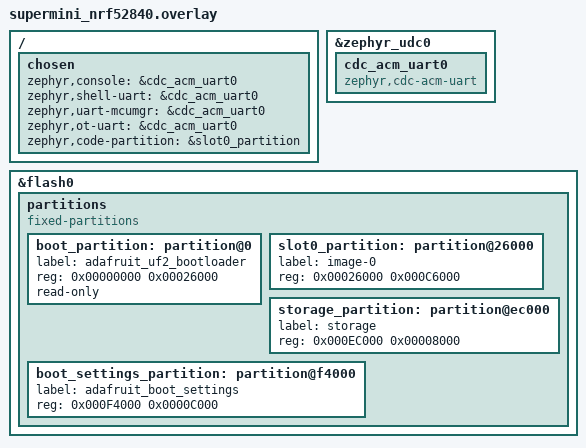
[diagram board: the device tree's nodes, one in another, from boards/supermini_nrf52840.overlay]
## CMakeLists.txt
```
#
# SuperMini nRF52840 Thread Network Health Checker
# Copyright (c) 2026 Antigravity
# SPDX-License-Identifier: Apache-2.0
#

cmake_minimum_required(VERSION 3.20.0)

find_package(Zephyr REQUIRED HINTS $ENV{ZEPHYR_BASE})
project(supermini_thread_health_checker)

target_sources(app PRIVATE
    src/main.cpp
    src/thread_health.cpp
)

target_include_directories(app PRIVATE src)
```

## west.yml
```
manifest:
  remotes:
    - name: zephyrproject-rtos
      url-base: https://github.com/zephyrproject-rtos

  defaults:
    remote: zephyrproject-rtos

  projects:
    - name: zephyr
      revision: v3.7.0
      import: true

  self:
    path: firmware
```

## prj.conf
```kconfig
#
# SuperMini nRF52840 Thread Network Health Checker - Zephyr & Matter Configuration
# Copyright (c) 2026 Antigravity
# SPDX-License-Identifier: Apache-2.0
#

# -----------------------------------------------------------------------------
# System & C++ Runtime
# -----------------------------------------------------------------------------
CONFIG_CPP=y
CONFIG_STD_CPP17=y
CONFIG_NEWLIB_LIBC=y
CONFIG_MAIN_STACK_SIZE=4096
CONFIG_SYSTEM_WORKQUEUE_STACK_SIZE=4096
CONFIG_HEAP_MEM_POOL_SIZE=16384
CONFIG_LOG=y
CONFIG_LOG_MODE_IMMEDIATE=y
CONFIG_PRINTK=y

# Flash Application Offset for Adafruit/nice!nano UF2 bootloader
CONFIG_FLASH_LOAD_OFFSET=0x26000
CONFIG_FLASH_LOAD_SIZE=0xc6000

# -----------------------------------------------------------------------------
# Clock Management (Crucial for SuperMini nRF52840 clones)
# Use internal 32.768 kHz RC oscillator to avoid hangs if external crystal is missing
# -----------------------------------------------------------------------------
CONFIG_CLOCK_CONTROL_NRF_K32SRC_RC=y
CONFIG_CLOCK_CONTROL_NRF_K32SRC_XTAL=n
CONFIG_CLOCK_CONTROL_NRF_K32SRC_500PPM=y

# -----------------------------------------------------------------------------
# USB CDC ACM Serial Console
# -----------------------------------------------------------------------------
CONFIG_USB_DEVICE_STACK=y
CONFIG_USB_DEVICE_PRODUCT="SuperMini Thread Health Checker"
CONFIG_USB_DEVICE_MANUFACTURER="Antigravity"
CONFIG_USB_DEVICE_VID=0x1915
CONFIG_USB_DEVICE_PID=0x520F
CONFIG_SERIAL=y
CONFIG_CONSOLE=y
CONFIG_UART_CONSOLE=y
CONFIG_UART_LINE_CTRL=y
CONFIG_USB_CDC_ACM=y

# -----------------------------------------------------------------------------
# OpenThread Network Stack (Full Thread Device / Router-capable)
# -----------------------------------------------------------------------------
CONFIG_NETWORKING=y
CONFIG_NET_L2_OPENTHREAD=y
CONFIG_SHELL=y
CONFIG_SHELL_BACKEND_SERIAL=y
CONFIG_OPENTHREAD_NORDIC_LIBRARY_FTD=y
CONFIG_OPENTHREAD_MANUAL_START=n
CONFIG_OPENTHREAD_SHELL=y
CONFIG_OPENTHREAD_PING_SENDER=y
CONFIG_OPENTHREAD_DIAG=y
CONFIG_NET_IPV6=y

# -----------------------------------------------------------------------------
# Bluetooth LE (Required for Matter BLE Commissioning)
# -----------------------------------------------------------------------------
CONFIG_BT=y
CONFIG_BT_PERIPHERAL=y
CONFIG_BT_DEVICE_NAME="SuperMini-Thread"
CONFIG_BT_SMP=y
CONFIG_BT_TINYCRYPT_ECC=y

# -----------------------------------------------------------------------------
# Matter (Project CHIP) Stack
# -----------------------------------------------------------------------------
CONFIG_CHIP=y
CONFIG_CHIP_ENABLE_PAIRING_AUTOSTART=y
CONFIG_CHIP_DEVICE_VENDOR_ID=65521
CONFIG_CHIP_DEVICE_PRODUCT_ID=32768
CONFIG_CHIP_DEVICE_TYPE=256
CONFIG_CHIP_DEVICE_DISCRIMINATOR=3840
CONFIG_CHIP_DEVICE_SPAKE2_PASSCODE=20202021
CONFIG_CHIP_COMMISSIONABLE_DEVICE_TYPE=y
CONFIG_CHIP_ENABLE_DNSSD_SRP=y

# -----------------------------------------------------------------------------
# Non-Volatile Storage (Thread Credentials & Fabric Storage)
# -----------------------------------------------------------------------------
CONFIG_FLASH=y
CONFIG_FLASH_PAGE_LAYOUT=y
CONFIG_NVS=y
CONFIG_SETTINGS=y
CONFIG_SETTINGS_NVS=y
```

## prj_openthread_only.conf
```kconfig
#
# SuperMini nRF52840 Thread Network Health Checker - Pure OpenThread Configuration
# Copyright (c) 2026 Antigravity
# SPDX-License-Identifier: Apache-2.0
#

# C++ Support
CONFIG_CPP=y
CONFIG_STD_CPP17=y
CONFIG_NEWLIB_LIBC=y
CONFIG_MAIN_STACK_SIZE=4096
CONFIG_SYSTEM_WORKQUEUE_STACK_SIZE=2048
CONFIG_HEAP_MEM_POOL_SIZE=8192
CONFIG_LOG=y
CONFIG_LOG_MODE_IMMEDIATE=y
CONFIG_PRINTK=y

# Flash Application Offset for Adafruit/nice!nano UF2 bootloader
CONFIG_USE_DT_CODE_PARTITION=y
CONFIG_FLASH_LOAD_OFFSET=0x26000
CONFIG_FLASH_LOAD_SIZE=0xc6000

# Internal 32.768 kHz RC oscillator safe fallback
CONFIG_CLOCK_CONTROL_NRF_K32SRC_RC=y
CONFIG_CLOCK_CONTROL_NRF_K32SRC_XTAL=n
CONFIG_CLOCK_CONTROL_NRF_K32SRC_500PPM=y

# USB CDC ACM Serial Console
CONFIG_USB_DEVICE_STACK=y
CONFIG_USB_DEVICE_PRODUCT="SuperMini Thread Health Checker (OT-CLI)"
CONFIG_USB_DEVICE_MANUFACTURER="Antigravity"
CONFIG_USB_DEVICE_VID=0x1915
CONFIG_USB_DEVICE_PID=0x520F
CONFIG_SERIAL=y
CONFIG_CONSOLE=y
CONFIG_UART_CONSOLE=y
CONFIG_UART_LINE_CTRL=y
CONFIG_USB_CDC_ACM=y

# Shell & OpenThread Shell
CONFIG_SHELL=y
CONFIG_SHELL_BACKEND_SERIAL=y

# OpenThread Stack
CONFIG_NETWORKING=y
CONFIG_NET_L2_OPENTHREAD=y
CONFIG_OPENTHREAD_FTD=y
CONFIG_OPENTHREAD_SOURCES=y
CONFIG_OPENTHREAD_MANUAL_START=y
CONFIG_OPENTHREAD_SHELL=y
CONFIG_OPENTHREAD_PING_SENDER=y
CONFIG_OPENTHREAD_DIAG=y
CONFIG_NET_IPV6=y

# Storage
CONFIG_FLASH=y
CONFIG_FLASH_PAGE_LAYOUT=y
CONFIG_NVS=y
CONFIG_SETTINGS=y
CONFIG_SETTINGS_NVS=y
```

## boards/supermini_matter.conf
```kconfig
#
# SuperMini nRF52840 Matter-over-Thread Configuration Overlay
# Copyright (c) 2026 Antigravity
# SPDX-License-Identifier: Apache-2.0
#

# -----------------------------------------------------------------------------
# Flash Layout & Adafruit/nice!nano UF2 Bootloader Offset
# -----------------------------------------------------------------------------
CONFIG_PARTITION_MANAGER_ENABLED=n
CONFIG_USE_DT_CODE_PARTITION=y
CONFIG_FLASH_LOAD_OFFSET=0x26000
CONFIG_FLASH_LOAD_SIZE=0xc6000

# -----------------------------------------------------------------------------
# Disable MCUboot & DFU (Standalone Image for Adafruit UF2 Bootloader)
# -----------------------------------------------------------------------------
CONFIG_BOOTLOADER_MCUBOOT=n
CONFIG_SECURE_BOOT=n
CONFIG_CHIP_OTA_REQUESTOR=n
CONFIG_CHIP_DFU_OVER_BT_SMP=n

# -----------------------------------------------------------------------------
# Disable Factory Data Generation (Use Kconfig Credentials Directly)
# -----------------------------------------------------------------------------
CONFIG_CHIP_FACTORY_DATA=n
CONFIG_CHIP_FACTORY_DATA_BUILD=n

# -----------------------------------------------------------------------------
# Clock Management (Crucial for SuperMini clones without 32kHz crystal)
# -----------------------------------------------------------------------------
CONFIG_CLOCK_CONTROL_NRF_K32SRC_RC=y
CONFIG_CLOCK_CONTROL_NRF_K32SRC_XTAL=n
CONFIG_CLOCK_CONTROL_NRF_K32SRC_500PPM=y

# -----------------------------------------------------------------------------
# Matter Commissioning & Credentials (Matching Google Home Manual Code 3497-011-2332)
# -----------------------------------------------------------------------------
CONFIG_CHIP=y
CONFIG_CHIP_ENABLE_PAIRING_AUTOSTART=y
CONFIG_CHIP_DEVICE_VENDOR_ID=65521
CONFIG_CHIP_DEVICE_PRODUCT_ID=32768
CONFIG_CHIP_DEVICE_DISCRIMINATOR=3840
CONFIG_CHIP_DEVICE_SPAKE2_PASSCODE=20202021
CONFIG_CHIP_COMMISSIONABLE_DEVICE_TYPE=y
CONFIG_CHIP_ENABLE_DNSSD_SRP=y

# -----------------------------------------------------------------------------
# USB CDC ACM Virtual Serial Console & OpenThread Diagnostics
# -----------------------------------------------------------------------------
CONFIG_USB_DEVICE_STACK=y
CONFIG_USB_DEVICE_PRODUCT="SuperMini Matter Thread Health Checker"
CONFIG_USB_DEVICE_MANUFACTURER="Antigravity"
CONFIG_USB_DEVICE_VID=0x1915
CONFIG_USB_DEVICE_PID=0x520F
CONFIG_SERIAL=y
CONFIG_CONSOLE=y
CONFIG_UART_CONSOLE=y
CONFIG_UART_LINE_CTRL=y
CONFIG_USB_CDC_ACM=y

# OpenThread Shell for mesh queries
CONFIG_OPENTHREAD_SHELL=y
CONFIG_OPENTHREAD_PING_SENDER=y
CONFIG_OPENTHREAD_DIAG=y
```

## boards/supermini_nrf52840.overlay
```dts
/*
 * SuperMini nRF52840 Device Tree Overlay
 *
 * Configures:
 * 1. USB CDC ACM Virtual Serial Port for Console and OpenThread CLI
 * 2. Adafruit / nice!nano UF2 Bootloader Safe Partition Map (Application at 0x26000)
 *
 * Copyright (c) 2026 Antigravity
 * SPDX-License-Identifier: Apache-2.0
 */

/ {
	chosen {
		zephyr,console = &cdc_acm_uart0;
		zephyr,shell-uart = &cdc_acm_uart0;
		zephyr,uart-mcumgr = &cdc_acm_uart0;
		zephyr,ot-uart = &cdc_acm_uart0;
		zephyr,code-partition = &slot0_partition;
	};
};

&zephyr_udc0 {
	cdc_acm_uart0: cdc_acm_uart0 {
		compatible = "zephyr,cdc-acm-uart";
	};
};

&flash0 {
	/delete-node/ partitions;

	partitions {
		compatible = "fixed-partitions";
		#address-cells = <1>;
		#size-cells = <1>;

		/* Reserved for Adafruit UF2 / nice!nano bootloader */
		boot_partition: partition@0 {
			label = "adafruit_uf2_bootloader";
			reg = <0x00000000 0x00026000>;
			read-only;
		};

		/* Application code partition (792 KB) */
		slot0_partition: partition@26000 {
			label = "image-0";
			reg = <0x00026000 0x000C6000>;
		};

		/* Non-volatile Settings / credentials storage (32 KB) */
		storage_partition: partition@ec000 {
			label = "storage";
			reg = <0x000EC000 0x00008000>;
		};

		/* Reserved for Adafruit bootloader config / settings (48 KB) */
		boot_settings_partition: partition@f4000 {
			label = "adafruit_boot_settings";
			reg = <0x000F4000 0x0000C000>;
		};
	};
};
```

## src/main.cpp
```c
/*
 * SuperMini nRF52840 Thread Network Health Checker
 *
 * Copyright (c) 2026 Antigravity
 * SPDX-License-Identifier: Apache-2.0
 */

#include <zephyr/kernel.h>
#include <zephyr/logging/log.h>
#include <zephyr/usb/usb_device.h>
#include <zephyr/drivers/uart.h>
#include <zephyr/net/openthread.h>
#include <stdio.h>

#include <openthread/instance.h>
#include <openthread/thread.h>
#include <openthread/cli.h>

#if defined(CONFIG_CHIP)
#include <app/server/Server.h>
#include <platform/CHIPDeviceLayer.h>
#include <setup_payload/QRCodeSetupPayloadGenerator.h>
#include <setup_payload/ManualSetupPayloadGenerator.h>
using namespace chip;
using namespace chip::DeviceLayer;
#endif

#include "thread_health.h"

LOG_MODULE_REGISTER(main, LOG_LEVEL_INF);

/* Standard Matter Test Commissioning Constants */
#define MATTER_TEST_VENDOR_ID     0xFFF1
#define MATTER_TEST_PRODUCT_ID    0x8000
#define MATTER_TEST_DISCRIMINATOR 3840
#define MATTER_TEST_PASSCODE      20202021
#define MATTER_MANUAL_PAIRING_CODE "34970112332"
#define MATTER_QR_CODE_PAYLOAD     "MT:Y.K9042C00KA0648G00"

static void init_usb_cdc_acm(void)
{
#if defined(CONFIG_USB_DEVICE_STACK)
    const struct device *const dev = DEVICE_DT_GET_ONE(zephyr_cdc_acm_uart);
    if (!device_is_ready(dev)) {
        LOG_WRN("CDC ACM device not ready");
        return;
    }

    int ret = usb_enable(NULL);
    if (ret != 0) {
        LOG_ERR("Failed to enable USB (%d)", ret);
        return;
    }

    LOG_INF("USB CDC ACM serial initialized successfully.");
#endif
}

static void print_banner(void)
{
    printf("\r\n\r\n");
    printf("######################################################################\r\n");
    printf("#     SuperMini nRF52840 Thread Health Checker & Matter Node        #\r\n");
    printf("######################################################################\r\n");
    printf("Hardware: Nordic nRF52840 SuperMini / nice!nano footprint\r\n");
    printf("Bootloader: Adafruit UF2 (Offset 0x26000 safe)\r\n");
    printf("Clock: Internal LFRC 32.768 kHz (XTAL-free safe fallback)\r\n");
    printf("----------------------------------------------------------------------\r\n");
    printf("MATTER COMMISSIONING CREDENTIALS (for Google Home App):\r\n");
    printf("  Device Type:          On/Off Light (0x0100)\r\n");
    printf("  Vendor ID (VID):      0x%04X (Test VID)\r\n", MATTER_TEST_VENDOR_ID);
    printf("  Product ID (PID):     0x%04X (Test PID)\r\n", MATTER_TEST_PRODUCT_ID);
    printf("  Discriminator:        %u\r\n", MATTER_TEST_DISCRIMINATOR);
    printf("  Setup Passcode:       %u\r\n", MATTER_TEST_PASSCODE);
    printf("  Manual Pairing Code:  %s\r\n", MATTER_MANUAL_PAIRING_CODE);
    printf("  QR Code Payload:      %s\r\n", MATTER_QR_CODE_PAYLOAD);
    printf("----------------------------------------------------------------------\r\n");
    printf("HOW TO PAIR WITH GOOGLE HOME:\r\n");
    printf("  1. Open Google Home app on your phone.\r\n");
    printf("  2. Tap '+' -> 'Set up a device' -> 'Matter-enabled device'.\r\n");
    printf("  3. Tap 'Set up without barcode' and enter: %s\r\n", MATTER_MANUAL_PAIRING_CODE);
    printf("  4. Google Home will commission the SuperMini over BLE and feed it\r\n");
    printf("     your Google Nest Thread network credentials.\r\n");
    printf("######################################################################\r\n\r\n");
}

int main(void)
{
    /* Initialize USB CDC ACM virtual serial port */
    init_usb_cdc_acm();

    /* Short delay for USB enumeration on host */
    k_sleep(K_MSEC(1500));

    /* Print startup banner and Matter pairing instructions */
    print_banner();

#if defined(CONFIG_CHIP)
    LOG_INF("Initializing Matter Server Stack...");
    CHIP_ERROR err = PlatformMgr().InitChipStack();
    if (err != CHIP_NO_ERROR) {
        LOG_ERR("PlatformMgr().InitChipStack() failed: %s", ErrorStr(err));
    } else {
        err = PlatformMgr().StartEventLoopTask();
        if (err != CHIP_NO_ERROR) {
            LOG_ERR("PlatformMgr().StartEventLoopTask() failed: %s", ErrorStr(err));
        }
    }
#endif

    /* Get OpenThread instance from Zephyr context */
    otInstance *ot_inst = openthread_get_default_instance();
    if (!ot_inst) {
        LOG_ERR("OpenThread instance not available!");
        return -1;
    }

    LOG_INF("OpenThread stack active. Initializing Health Diagnostic Engine...");
    thread_health_init(ot_inst);

    LOG_INF("System ready. OpenThread CLI is active on this serial port.");
    return 0;
}
```

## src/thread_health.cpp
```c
/*
 * SuperMini nRF52840 Thread Network Health Checker
 *
 * Copyright (c) 2026 Antigravity
 * SPDX-License-Identifier: Apache-2.0
 */

#include "thread_health.h"
#include <zephyr/logging/log.h>
#include <zephyr/net/openthread.h>
#include <stdio.h>
#include <string.h>

LOG_MODULE_REGISTER(thread_health, LOG_LEVEL_INF);

static otInstance *s_ot_instance = NULL;
static uint32_t s_last_ping_rtt = 0;
static bool s_ping_in_progress = false;
static bool s_ping_success = false;

/* Stack and thread definition for health monitor */
#define HEALTH_STACK_SIZE 2048
#define HEALTH_PRIORITY   7

K_THREAD_STACK_DEFINE(s_health_stack, HEALTH_STACK_SIZE);
static struct k_thread s_health_thread_data;

static const char *role_to_string(otDeviceRole role)
{
    switch (role) {
    case OT_DEVICE_ROLE_DISABLED: return "DISABLED";
    case OT_DEVICE_ROLE_DETACHED: return "DETACHED";
    case OT_DEVICE_ROLE_CHILD:    return "CHILD (FED/SED)";
    case OT_DEVICE_ROLE_ROUTER:   return "ROUTER";
    case OT_DEVICE_ROLE_LEADER:   return "LEADER";
    default:                      return "UNKNOWN";
    }
}

static void ping_reply_callback(const otPingSenderReply *aReply, void *aContext)
{
    ARG_UNUSED(aContext);
    s_last_ping_rtt = aReply->mRoundTripTime;
    s_ping_success = true;
    s_ping_in_progress = false;
}

static void ping_stats_callback(const otPingSenderStatistics *aStatistics, void *aContext)
{
    ARG_UNUSED(aContext);
    ARG_UNUSED(aStatistics);
    s_ping_in_progress = false;
}

void thread_health_init(otInstance *instance)
{
    s_ot_instance = instance;

    k_thread_create(&s_health_thread_data, s_health_stack,
                    K_THREAD_STACK_SIZEOF(s_health_stack),
                    thread_health_worker,
                    NULL, NULL, NULL,
                    HEALTH_PRIORITY, 0, K_MSEC(3000));
}

void thread_health_collect(thread_health_snapshot_t *snapshot)
{
    if (!s_ot_instance || !snapshot) {
        return;
    }

    memset(snapshot, 0, sizeof(thread_health_snapshot_t));

    openthread_api_mutex_lock(openthread_get_default_context());

    snapshot->role = otThreadGetDeviceRole(s_ot_instance);
    snapshot->rloc16 = otThreadGetRloc16(s_ot_instance);
    snapshot->partitionId = otThreadGetPartitionId(s_ot_instance);

    /* Operational Dataset */
    otOperationalDataset dataset;
    if (otDatasetGetActive(s_ot_instance, &dataset) == OT_ERROR_NONE) {
        if (dataset.mComponents.mIsChannelPresent) {
            snapshot->channel = dataset.mChannel;
        }
        if (dataset.mComponents.mIsPanIdPresent) {
            snapshot->panId = dataset.mPanId;
        }
        if (dataset.mComponents.mIsNetworkNamePresent) {
            strncpy(snapshot->networkName, dataset.mNetworkName.m8, OT_NETWORK_NAME_MAX_SIZE);
            snapshot->networkName[OT_NETWORK_NAME_MAX_SIZE] = '\0';
        }
        if (dataset.mComponents.mIsExtendedPanIdPresent) {
            memcpy(snapshot->extPanId, dataset.mExtendedPanId.m8, OT_EXT_PAN_ID_SIZE);
        }
    }

    /* Parent Link info if Child */
    if (snapshot->role == OT_DEVICE_ROLE_CHILD) {
        otRouterInfo parentInfo;
        if (otThreadGetParentInfo(s_ot_instance, &parentInfo) == OT_ERROR_NONE) {
            snapshot->hasParent = true;
            snapshot->parentLqi = parentInfo.mLinkQualityIn;
            int8_t avgRssi = 0;
            otThreadGetParentAverageRssi(s_ot_instance, &avgRssi);
            snapshot->parentRssi = avgRssi;
            snapshot->parentMargin = parentInfo.mPathCost;
        }
    }

    /* Neighbor table iteration */
    otNeighborInfoIterator iterator = OT_NEIGHBOR_INFO_ITERATOR_INIT;
    otNeighborInfo neighbor;
    uint8_t count = 0;

    while (count < MAX_TRACKED_NEIGHBORS &&
           otThreadGetNextNeighborInfo(s_ot_instance, &iterator, &neighbor) == OT_ERROR_NONE) {
        snapshot->neighbors[count].rloc16 = neighbor.mRloc16;
        memcpy(&snapshot->neighbors[count].extAddress, &neighbor.mExtAddress, sizeof(otExtAddress));
        snapshot->neighbors[count].avgRssi = neighbor.mAverageRssi;
        snapshot->neighbors[count].lastRssi = neighbor.mLastRssi;
        snapshot->neighbors[count].lqi = neighbor.mLinkQualityIn;
        snapshot->neighbors[count].margin = neighbor.mLinkMargin;
        snapshot->neighbors[count].frameErrorRate = (uint16_t)(((uint32_t)neighbor.mFrameErrorRate * 10000) / 0xFFFF);
        snapshot->neighbors[count].isChild = neighbor.mIsChild;
        count++;
    }
    snapshot->neighborCount = count;

    /* Search for Border Router Prefix (OMR or default route) */
    otNetworkDataIterator netDataIter = OT_NETWORK_DATA_ITERATOR_INIT;
    otBorderRouterConfig config;
    while (otNetDataGetNextOnMeshPrefix(s_ot_instance, &netDataIter, &config) == OT_ERROR_NONE) {
        if (config.mDefaultRoute || config.mOnMesh) {
            snapshot->borderRouterFound = true;
            /* Use prefix to construct border router target IP (::1) */
            memcpy(snapshot->borderRouterIp.mFields.m8, config.mPrefix.mPrefix.mFields.m8, 8);
            snapshot->borderRouterIp.mFields.m8[15] = 0x01;
            break;
        }
    }

    snapshot->lastPingRttMs = s_last_ping_rtt;
    snapshot->pingSuccess = s_ping_success;

    openthread_api_mutex_unlock(openthread_get_default_context());
}

void thread_health_print(const thread_health_snapshot_t *snapshot)
{
    if (!snapshot) {
        return;
    }

    printf("\r\n======================================================================\r\n");
    printf("[THREAD HEALTH CHECKER - SuperMini nRF52840]\r\n");
    printf("State: %-16s | Channel: %2d | PAN ID: 0x%04X\r\n",
           role_to_string(snapshot->role), snapshot->channel, snapshot->panId);
    printf("Network Name: %-16s | RLOC16: 0x%04X | Partition ID: 0x%08X\r\n",
           snapshot->networkName[0] ? snapshot->networkName : "Not Commissioned",
           snapshot->rloc16, snapshot->partitionId);
    printf("----------------------------------------------------------------------\r\n");

    /* Parent Link */
    if (snapshot->hasParent) {
        printf("PARENT LINK: Avg RSSI: %3d dBm | LQI: %u/3 | Link Margin: %2d dB\r\n",
               snapshot->parentRssi, snapshot->parentLqi, snapshot->parentMargin);
        printf("----------------------------------------------------------------------\r\n");
    }

    /* Neighbors Table */
    printf("NEIGHBOR NODES (%u discovered):\r\n", snapshot->neighborCount);
    if (snapshot->neighborCount == 0) {
        printf("  (No direct 802.15.4 neighbors heard yet)\r\n");
    } else {
        printf("  # | RLOC16 | Extended MAC Address   | Avg RSSI | Last RSSI | Margin | LQI | FER\r\n");
        for (uint8_t i = 0; i < snapshot->neighborCount; i++) {
            const otExtAddress *mac = &snapshot->neighbors[i].extAddress;
            printf("  %u | 0x%04X | %02X:%02X:%02X:%02X:%02X:%02X:%02X:%02X |  %4d dBm |   %4d dBm |  %2d dB |  %u  | %u.%02u%%\r\n",
                   i + 1,
                   snapshot->neighbors[i].rloc16,
                   mac->m8[0], mac->m8[1], mac->m8[2], mac->m8[3],
                   mac->m8[4], mac->m8[5], mac->m8[6], mac->m8[7],
                   snapshot->neighbors[i].avgRssi,
                   snapshot->neighbors[i].lastRssi,
                   snapshot->neighbors[i].margin,
                   snapshot->neighbors[i].lqi,
                   snapshot->neighbors[i].frameErrorRate / 100,
                   snapshot->neighbors[i].frameErrorRate % 100);
        }
    }
    printf("----------------------------------------------------------------------\r\n");

    /* Border Router Connectivity */
    if (snapshot->borderRouterFound) {
        printf("GOOGLE NEST BORDER ROUTER: %s | Ping Latency: %u ms\r\n",
               snapshot->pingSuccess ? "ONLINE" : "NO REPLY",
               snapshot->lastPingRttMs);
    } else {
        printf("GOOGLE NEST BORDER ROUTER: Searching for OMR Prefix...\r\n");
    }
    printf("======================================================================\r\n");
}

void thread_health_ping_border_router(void)
{
    if (!s_ot_instance || s_ping_in_progress) {
        return;
    }

    openthread_api_mutex_lock(openthread_get_default_context());

    otDeviceRole role = otThreadGetDeviceRole(s_ot_instance);
    if (role == OT_DEVICE_ROLE_CHILD || role == OT_DEVICE_ROLE_ROUTER || role == OT_DEVICE_ROLE_LEADER) {
        otPingSenderConfig pingConfig;
        memset(&pingConfig, 0, sizeof(pingConfig));

        /* Ping leader or discovered border router */
        otLeaderData leaderData;
        const otIp6Address *leaderAddr = NULL;
        if (otThreadGetLeaderData(s_ot_instance, &leaderData) == OT_ERROR_NONE) {
            leaderAddr = otThreadGetRloc(s_ot_instance);
        }

        if (leaderAddr) {
            pingConfig.mDestination = *leaderAddr;
            pingConfig.mCount = 1;
            pingConfig.mInterval = 1000;
            pingConfig.mTimeout = 1000;
            pingConfig.mReplyCallback = ping_reply_callback;
            pingConfig.mStatisticsCallback = ping_stats_callback;

            s_ping_in_progress = true;
            s_ping_success = false;
            otPingSenderPing(s_ot_instance, &pingConfig);
        }
    }

    openthread_api_mutex_unlock(openthread_get_default_context());
}

void thread_health_worker(void *p1, void *p2, void *p3)
{
    ARG_UNUSED(p1);
    ARG_UNUSED(p2);
    ARG_UNUSED(p3);

    thread_health_snapshot_t snapshot;

    while (1) {
        k_sleep(K_SECONDS(5));

        if (s_ot_instance) {
            thread_health_ping_border_router();
            k_sleep(K_MSEC(500));
            thread_health_collect(&snapshot);
            thread_health_print(&snapshot);
        }
    }
}
```

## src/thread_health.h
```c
/*
 * SuperMini nRF52840 Thread Network Health Checker
 *
 * Copyright (c) 2026 Antigravity
 * SPDX-License-Identifier: Apache-2.0
 */

#ifndef THREAD_HEALTH_H_
#define THREAD_HEALTH_H_

#include <zephyr/kernel.h>
#include <openthread/instance.h>
#include <openthread/thread.h>
#include <openthread/link.h>
#include <openthread/dataset.h>
#include <openthread/netdata.h>
#include <openthread/ip6.h>
#include <openthread/ping_sender.h>

#ifdef __cplusplus
extern "C" {
#endif

/* Maximum neighbors tracked in single snapshot */
#define MAX_TRACKED_NEIGHBORS 16

/* Diagnostic structure representing current link & mesh health */
typedef struct {
    otDeviceRole role;
    uint16_t rloc16;
    uint32_t partitionId;
    uint16_t channel;
    uint16_t panId;
    char networkName[OT_NETWORK_NAME_MAX_SIZE + 1];
    uint8_t extPanId[OT_EXT_PAN_ID_SIZE];

    /* Parent link if Child */
    bool hasParent;
    int8_t parentRssi;
    uint8_t parentLqi;
    uint8_t parentMargin;

    /* Neighbor statistics */
    uint8_t neighborCount;
    struct {
        uint16_t rloc16;
        otExtAddress extAddress;
        int8_t avgRssi;
        int8_t lastRssi;
        uint8_t lqi;
        uint8_t margin;
        uint16_t frameErrorRate; /* In percentage * 100 (e.g. 250 = 2.5%) */
        bool isChild;
    } neighbors[MAX_TRACKED_NEIGHBORS];

    /* Border Router ping latency */
    bool borderRouterFound;
    otIp6Address borderRouterIp;
    uint32_t lastPingRttMs;
    bool pingSuccess;
} thread_health_snapshot_t;

/**
 * @brief Initialize the Thread Health Checker engine.
 * @param instance OpenThread instance pointer.
 */
void thread_health_init(otInstance *instance);

/**
 * @brief Collect a health snapshot from OpenThread.
 * @param snapshot Output pointer to store current metrics.
 */
void thread_health_collect(thread_health_snapshot_t *snapshot);

/**
 * @brief Print formatted health dashboard over serial console.
 * @param snapshot Snapshot data to format and print.
 */
void thread_health_print(const thread_health_snapshot_t *snapshot);

/**
 * @brief Trigger an ICMPv6 ping to the Google Nest / Thread Border Router.
 */
void thread_health_ping_border_router(void);

/**
 * @brief Thread Health background worker thread entrypoint.
 */
void thread_health_worker(void *p1, void *p2, void *p3);

#ifdef __cplusplus
}
#endif

#endif /* THREAD_HEALTH_H_ */
```
